# FM33A0XXER register map
File version: 1.0
ARM 32-bit Cortex SC000 Microcontroller based device
CPU: SC000, little endian, no MPU, no FPU, 3 interrupt priority bits
Registers are 32-bit, read-write, reset 0x0 unless marked. A register's access mark holds for its fields unless they carry their own. Offsets are from the block's base; lines under a group give offsets from that group; [hi:lo] are bit positions; {n}, {i} and the like mark numbered series; 'fields as' and 'values as' point back to an identical list; <NAME> marks a mode.

## Memory map
0x40000000 DBG size 0x8 — DBG module information
0x40000400 DMA size 0x138 — DMA module information
0x40000800 QSPI size 0x30 — QSPI module information
0x40000C00 GPIOA size 0x2C — GPIOA module information
0x40000C40 GPIOB size 0x2C — GPIOB module information
0x40000C80 GPIOC size 0x2C — GPIOC module information
0x40000CC0 GPIOD size 0x2C — GPIOD module information
0x40000D00 GPIOE size 0x2C — GPIOE module information
0x40000D40 GPIOF size 0x2C — GPIOF module information
0x40000D80 GPIOG size 0x2C — GPIOG module information
0x40000DC0 GPIO size 0x144 — GPIO module information
0x40001000 FLS size 0x58 — FLS module information
0x40001400 PAE size 0x20 — PAE module information
0x40001800 HASH size 0x8 — HASH module information
0x40002000 PMU size 0x14 — PMU module information
0x40002400 CMU size 0x38 — CMU module information
0x40002800 RMU size 0x24 — RMU module information
0x40010000 CRC size 0x20 — CRC module information
0x40010400 SPI0 size 0x1C — SPI0 module information
0x40010800 SPI1 size 0x1C — SPI1 module information
0x40010C00 LCD size 0x60 — LCD module information
0x40011000 RTCVT size 0x80 — RTCVT module information
0x40011400 IWDT size 0xC — IWDT module information
0x40011800 WWDT size 0x18 — WWDT module information
0x40011C00 U7816 size 0x24 — U7816 module information
0x40012000 UART0 size 0x1C — UART0 module information
0x40012400 I2C0 size 0x24 — I2C0 module information
0x40012800 SVD size 0x14 — SVD module information
0x40013000 BT1 size 0x44 — BT1 module information
0x40013044 BT2 size 0x44 — BT2 module information
0x40013090 ET1 size 0x20 — ET1 module information
0x400130B0 ET2 size 0x20 — ET2 module information
0x400130D0 ET3 size 0x20 — ET3 module information
0x400130F0 ET4 size 0x20 — ET4 module information
0x40013400 LPTIM size 0x30 — LPTIM module information
0x40013800 AES size 0x54 — AES module information
0x40013C00 RNG size 0x20 — RNG module information
0x40014000 LPUART0 size 0x1C — LPUART0 module information
0x40014400 LPUART1 size 0x1C — LPUART1 module information
0x40014800 SPI2 size 0x1C — SPI2 module information
0x40014C00 SPI3 size 0x1C — SPI3 module information
0x40015000 I2C1 size 0x24 — I2C1 module information
0x40015400 COMP size 0x14 — COMP module information
0x40015C00 CIC size 0x14 — CIC module information
0x40016000 BSTIM size 0x30 — BSTIM module information
0x40016400 SPI4 size 0x1C — SPI4 module information
0x40016800 UART1 size 0x1C — UART1 module information
0x40016C00 UART2 size 0x1C — UART2 module information
0x40017000 UART3 size 0x1C — UART3 module information
0x40017400 UART4 size 0x1C — UART4 module information
0x40017800 UART5 size 0x1C — UART5 module information
0x40017C00 UART size 0x1C — UART module information
0x4001E000 CDIF size 0x8 — CDIF module information
0x4001F000 RTC size 0x7C — RTC module information
0x4001F800 VRTC size 0x1C — VRTC module information
0x4001FA00 ADC size 0x14 — ADC module information
0x4001FC00 GPIOH size 0x14 — GPIOH module information

## PMU — PMU module information
Base 0x40002000
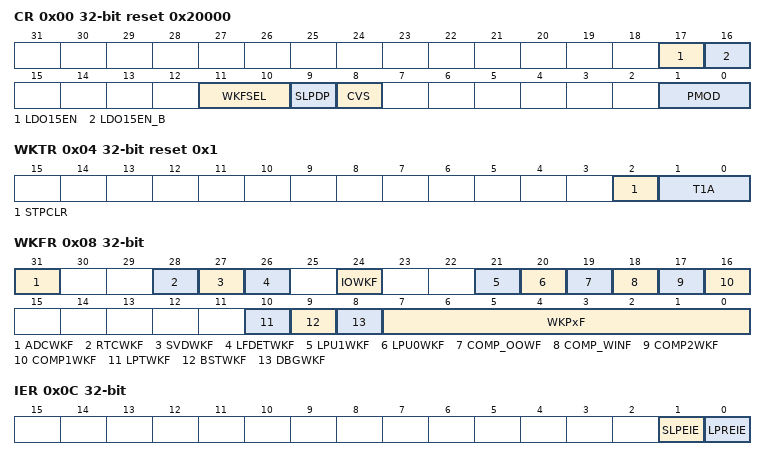
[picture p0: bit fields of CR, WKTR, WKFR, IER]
0x00 CR reset 0x20000 — Power Management Control Register
  [17] LDO15EN ro — LDO15EN field description
  [16] LDO15EN_B ro — LDO15EN_B field description
  [11:10] WKFSEL — WKFSEL field description
  [9] SLPDP — SLPDP field description
  [8] CVS — CVS field description
  [1:0] PMOD — PMOD field description
0x04 WKTR reset 0x1 — Wakeup Time Register
  [2] STPCLR — STPCLR field description
  [1:0] T1A — T1A field description
0x08 WKFR — Wakeup Source Flags Register
  [31] ADCWKF ro — ADCWKF field description
  [28] RTCWKF ro — RTCWKF field description
  [27] SVDWKF ro — SVDWKF field description
  [26] LFDETWKF ro — LFDETWKF field description
  [24] IOWKF ro — IOWKF field description
  [21] LPU1WKF ro — LPU1WKF field description
  [20] LPU0WKF ro — LPU0WKF field description
  [19] COMP_OOWF ro — COMP_OOWF field description
  [18] COMP_WINF ro — COMP_WINF field description
  [17] COMP2WKF ro — COMP2WKF field description
  [16] COMP1WKF ro — COMP1WKF field description
  [10] LPTWKF ro — LPTWKF field description
  [9] BSTWKF ro — BSTWKF field description
  [8] DBGWKF — DBGWKF field description
  [7:0] WKPxF — WKPxF field description
0x0C IER — PMU Interrupt Enable Register
  [1] SLPEIE — SLPEIE field description
  [0] LPREIE — LPREIE field description
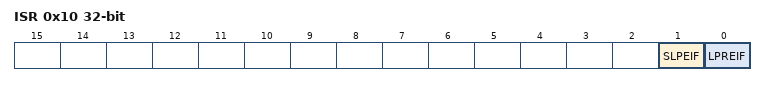
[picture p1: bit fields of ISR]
0x10 ISR — PMU Interrupt and Status Register
  [1] SLPEIF — SLPEIF field description
  [0] LPREIF — LPREIF field description
